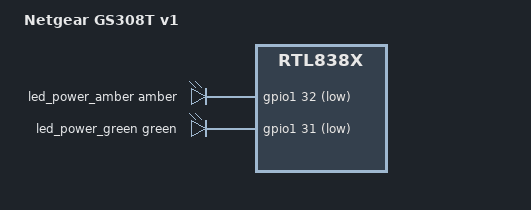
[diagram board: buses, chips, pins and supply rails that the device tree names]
// SPDX-License-Identifier: GPL-2.0-or-later

#include "rtl8380_netgear_gigabit.dtsi"

#include <dt-bindings/leds/common.h>

/ {
	compatible = "netgear,gs308t-v1", "realtek,rtl838x-soc";
	model = "Netgear GS308T v1";

	aliases {
		led-boot = &led_power_green;
		led-failsafe = &led_power_amber;
		led-running = &led_power_green;
		led-upgrade = &led_power_amber;
	};

	leds {
		compatible = "gpio-leds";

		led_power_amber: led-0 {
			color = <LED_COLOR_ID_AMBER>;
			function = LED_FUNCTION_POWER;
			gpios = <&gpio1 32 GPIO_ACTIVE_LOW>;
		};

		led_power_green: led-1 {
			color = <LED_COLOR_ID_GREEN>;
			function = LED_FUNCTION_POWER;
			gpios = <&gpio1 31 GPIO_ACTIVE_LOW>;
		};
	};
};

&firmware {
	openwrt,ih-magic = <0x4e474335>;
};
